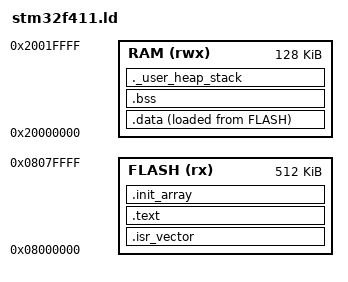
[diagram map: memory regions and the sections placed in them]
/*
 * Linker script for STM32F411CEU6
 * Flash: 512K starting at 0x08000000
 * RAM:   128K starting at 0x20000000
 */

ENTRY(Reset_Handler)

MEMORY
{
    FLASH (rx)  : ORIGIN = 0x08000000, LENGTH = 512K
    RAM   (rwx) : ORIGIN = 0x20000000, LENGTH = 128K
}

/* Minimum sizes reserved for heap and stack; adjust if you use more RAM */
_Min_Heap_Size  = 0x400;
_Min_Stack_Size = 0x400;

SECTIONS
{
    .isr_vector :
    {
        . = ALIGN(4);
        KEEP(*(.isr_vector))
        . = ALIGN(4);
    } > FLASH

    .text :
    {
        . = ALIGN(4);
        *(.text*)
        *(.rodata*)
        . = ALIGN(4);
    } > FLASH

    /* Needed by some libc bits (e.g. __libc_init_array/exit handlers) if
     * you later enable C++ or static constructors. Harmless if empty. */
    .init_array :
    {
        . = ALIGN(4);
        PROVIDE_HIDDEN(__init_array_start = .);
        KEEP(*(.init_array*))
        PROVIDE_HIDDEN(__init_array_end = .);
        . = ALIGN(4);
    } > FLASH

    _sidata = LOADADDR(.data);

    .data :
    {
        . = ALIGN(4);
        _sdata = .;
        *(.data*)
        . = ALIGN(4);
        _edata = .;
    } > RAM AT> FLASH

    .bss :
    {
        . = ALIGN(4);
        _sbss = .;
        *(.bss*)
        *(COMMON)
        . = ALIGN(4);
        _ebss = .;
    } > RAM

    ._user_heap_stack :
    {
        . = ALIGN(8);
        PROVIDE(end = .);
        . = . + _Min_Heap_Size;
        . = . + _Min_Stack_Size;
        . = ALIGN(8);
    } > RAM

    _end = end;
    _estack = ORIGIN(RAM) + LENGTH(RAM);

    /DISCARD/ :
    {
        *(.comment)
        *(.ARM.attributes)
    }
}
